# MKV10Z7 register map
Vendor: Freescale Semiconductor, Inc.; File version: 1.6
MKV10Z7 Freescale Microcontroller
CPU: CM0PLUS r0p0, little endian, no MPU, no FPU, 0x2 interrupt priority bits, 0x0 interrupts
Registers are 32-bit, read-write, reset 0x0 unless marked. A register's access mark holds for its fields unless they carry their own. Offsets are from the block's base; lines under a group give offsets from that group; [hi:lo] are bit positions; {n}, {i} and the like mark numbered series; 'fields as' and 'values as' point back to an identical list; <NAME> marks a mode.

## Memory map
0x00000400 FTFA_FlashConfig size 0xE — Flash configuration field
0x40008000 DMA size 0x1080 — Enhanced direct memory access controller
0x40020000 FTFA size 0x14 — Flash Memory Interface
0x40021000 DMAMUX size 0x4 — DMA channel multiplexor
0x4002C000 SPI0 size 0x140 — Serial Peripheral Interface
0x40032000 CRC size 0xC — Cyclic Redundancy Check
0x40036000 PDB0 size 0x19C — Programmable Delay Block
0x40038000 FTM0 size 0x9C — FlexTimer Module
0x40039000 FTM1 size 0x9C — FlexTimer Module
0x4003A000 FTM2 size 0x9C — FlexTimer Module
0x4003B000 ADC0 size 0x70 — Analog-to-Digital Converter
0x4003C000 ADC1 size 0x70 — Analog-to-Digital Converter
0x4003F000 DAC0 size 0x24 — 12-Bit Digital-to-Analog Converter
0x40040000 LPTMR0 size 0x10 — Low Power Timer
0x40047000 SIM size 0x1104 — System Integration Module
0x40049000 PORTA size 0xA4 — Pin Control and Interrupts
0x4004A000 PORTB size 0xA4 — Pin Control and Interrupts
0x4004B000 PORTC size 0xA4 — Pin Control and Interrupts
0x4004C000 PORTD size 0xA4 — Pin Control and Interrupts
0x4004D000 PORTE size 0xA4 — Pin Control and Interrupts
0x40052000 WDOG size 0x18 — Generation 2008 Watchdog Timer
0x40061000 EWM size 0x6 — External Watchdog Monitor
0x40064000 MCG size 0xC — Multipurpose Clock Generator module
0x40065000 OSC0 size 0x1 — Oscillator
0x40066000 I2C0 size 0xC — Inter-Integrated Circuit
0x4006A000 UART0 size 0x17 — Serial Communication Interface
0x4006B000 UART1 size 0x17 — Serial Communication Interface
0x40073000 CMP0 size 0x6 — High-Speed Comparator (CMP), Voltage Reference (VREF) Digital-to-Analog Converter (DAC), and Analog Mux (ANMUX)
0x40073008 CMP1 size 0x6 — High-Speed Comparator (CMP), Voltage Reference (VREF) Digital-to-Analog Converter (DAC), and Analog Mux (ANMUX)
0x4007C000 LLWU size 0xA — Low leakage wakeup unit
0x4007D000 PMC size 0x3 — Power Management Controller
0x4007E000 SMC size 0x4 — System Mode Controller
0x4007F000 RCM size 0x6 — Reset Control Module
0x400FF000 GPIOA size 0x18 — General Purpose Input/Output
0x400FF040 GPIOB size 0x18 — General Purpose Input/Output
0x400FF080 GPIOC size 0x18 — General Purpose Input/Output
0x400FF0C0 GPIOD size 0x18 — General Purpose Input/Output
0x400FF100 GPIOE size 0x18 — General Purpose Input/Output
0xF0000000 MTB size 0x1000 — Micro Trace Buffer
0xF0001000 MTBDWT size 0x1000 — MTB data watchpoint and trace
0xF0002000 ROM size 0x1000 — System ROM
0xF0003000 MCM blocks up to offset 0x44 — Core Platform Miscellaneous Control Module
0xF0004000 MMDVSQ size 0x14 — Memory-Mapped Divide and Square Root
0xF8000000 FGPIOA size 0x18 — General Purpose Input/Output
0xF8000040 FGPIOB size 0x18 — General Purpose Input/Output
0xF8000080 FGPIOC size 0x18 — General Purpose Input/Output
0xF80000C0 FGPIOD size 0x18 — General Purpose Input/Output
0xF8000100 FGPIOE size 0x18 — General Purpose Input/Output

## Interrupts
0 DMA0 (DMA)
1 DMA1 (DMA)
2 DMA2 (DMA)
3 DMA3 (DMA)
4 DMA_Error (DMA)
5 FTFA
6 PMC
7 LLWU
8 I2C0
10 SPI0
12 UART0
13 UART1
15 ADC0
16 ADC1
17 FTM0
18 FTM1
19 FTM2
20 CMP0
21 CMP1
23 WDOG_EWM (WDOG, EWM)
25 DAC0
27 MCG
28 LPTMR0
29 PDB0
30 PORTA (PORTA, GPIOA)
31 PORTBCDE (PORTB, PORTC, PORTD, PORTE, GPIOB, GPIOC, GPIOD, GPIOE)

## FTFA_FlashConfig — Flash configuration field
Base 0x00000400; register names take the prefix NV_
0x00 BACKKEY3 8-bit ro reset 0xFF — Backdoor Comparison Key 3.
  [7:0] KEY — Backdoor Comparison Key.
0x01 BACKKEY2 8-bit ro reset 0xFF — Backdoor Comparison Key 2.
  [7:0] KEY — Backdoor Comparison Key.
0x02 BACKKEY1 8-bit ro reset 0xFF — Backdoor Comparison Key 1.
  [7:0] KEY — Backdoor Comparison Key.
0x03 BACKKEY0 8-bit ro reset 0xFF — Backdoor Comparison Key 0.
  [7:0] KEY — Backdoor Comparison Key.
0x04 BACKKEY7 8-bit ro reset 0xFF — Backdoor Comparison Key 7.
  [7:0] KEY — Backdoor Comparison Key.
0x05 BACKKEY6 8-bit ro reset 0xFF — Backdoor Comparison Key 6.
  [7:0] KEY — Backdoor Comparison Key.
0x06 BACKKEY5 8-bit ro reset 0xFF — Backdoor Comparison Key 5.
  [7:0] KEY — Backdoor Comparison Key.
0x07 BACKKEY4 8-bit ro reset 0xFF — Backdoor Comparison Key 4.
  [7:0] KEY — Backdoor Comparison Key.
0x08 FPROT3 8-bit ro reset 0xFF — Non-volatile P-Flash Protection 1 - Low Register
  [7:0] PROT — P-Flash Region Protect
0x09 FPROT2 8-bit ro reset 0xFF — Non-volatile P-Flash Protection 1 - High Register
  [7:0] PROT — P-Flash Region Protect
0x0A FPROT1 8-bit ro reset 0xFF — Non-volatile P-Flash Protection 0 - Low Register
  [7:0] PROT — P-Flash Region Protect
0x0B FPROT0 8-bit ro reset 0xFF — Non-volatile P-Flash Protection 0 - High Register
  [7:0] PROT — P-Flash Region Protect
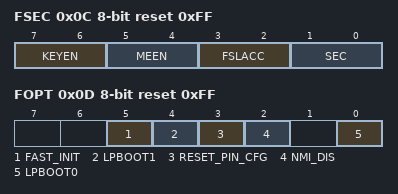
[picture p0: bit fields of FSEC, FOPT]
0x0C FSEC 8-bit ro reset 0xFF — Non-volatile Flash Security Register
  [7:6] KEYEN — Backdoor Key Security Enable
    2=Backdoor key access enabled; 3=Backdoor key access disabled
  [5:4] MEEN
    2=Mass erase is disabled; 3=Mass erase is enabled
  [3:2] FSLACC — Freescale Failure Analysis Access Code
    2=Freescale factory access denied; 3=Freescale factory access granted
  [1:0] SEC — Flash Security
    2=MCU security status is unsecure; 3=MCU security status is secure
0x0D FOPT 8-bit ro reset 0xFF — Non-volatile Flash Option Register
  [5] FAST_INIT
    0=Slower initialization; 1=Fast Initialization
  [4] LPBOOT1
    0=Core and system clock divider (OUTDIV1) is 0x7 (divide by 8) when LPBOOT0=0 or 0x3 (divide by 4) when LPBOOT0=1; 1=Core and system clock divider (OUTDIV1) is 0x1 (divide by 2) when LPBOOT0=0 or 0x0 (divide by 1) when LPBOOT0=1
  [3] RESET_PIN_CFG
    0=RESET pin is disabled following a POR and cannot be enabled as reset function; 1=RESET_b pin is dedicated
  [2] NMI_DIS
    0=NMI interrupts are always blocked; 1=NMI_b pin/interrupts reset default to enabled
  [0] LPBOOT0
    0=Core and system clock divider (OUTDIV1) is 0x7 (divide by 8) when LPBOOT1=0 or 0x1 (divide by 2) when LPBOOT1=1; 1=Core and system clock divider (OUTDIV1) is 0x3 (divide by 4) when LPBOOT1=0 or 0x0 (divide by 1) when LPBOOT1=1
